# ATmega16U2 device description
Architecture: AVR8; Family: megaAVR
Registers are 8-bit, access not given, no defined reset value unless marked. A register's access mark holds for its fields unless they carry their own. Offsets are from the block's base; [hi:lo] are bit positions.

## TC1 (TC16 module) — Timer/Counter, 16-bit
Instances: TC1 0x00
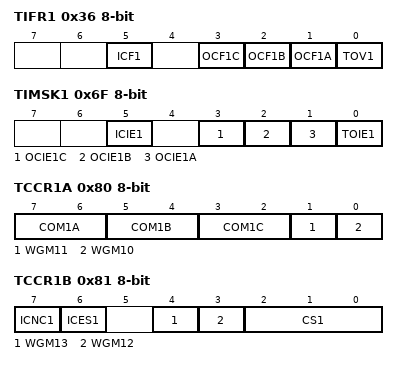
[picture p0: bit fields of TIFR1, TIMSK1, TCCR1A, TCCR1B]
0x36 TIFR1 — Timer/Counter1 Interrupt Flag register
  [5] ICF1 — Input Capture Flag 1
  [3] OCF1C — Output Compare Flag 1C
  [2] OCF1B — Output Compare Flag 1B
  [1] OCF1A — Output Compare Flag 1A
  [0] TOV1 — Timer/Counter1 Overflow Flag
0x6F TIMSK1 — Timer/Counter1 Interrupt Mask Register
  [5] ICIE1 — Timer/Counter1 Input Capture Interrupt Enable
  [3] OCIE1C — Timer/Counter1 Output Compare C Match Interrupt Enable
  [2] OCIE1B — Timer/Counter1 Output Compare B Match Interrupt Enable
  [1] OCIE1A — Timer/Counter1 Output Compare A Match Interrupt Enable
  [0] TOIE1 — Timer/Counter1 Overflow Interrupt Enable
0x80 TCCR1A — Timer/Counter1 Control Register A
  [7:6] COM1A — Compare Output Mode 1A, bits
  [5:4] COM1B — Compare Output Mode 1B, bits
  [3:2] COM1C — Compare Output Mode 1C, bits
  [1] WGM11 — Waveform Generation Mode
  [0] WGM10 — Waveform Generation Mode
0x81 TCCR1B — Timer/Counter1 Control Register B
  [7] ICNC1 — Input Capture 1 Noise Canceler
  [6] ICES1 — Input Capture 1 Edge Select
  [4] WGM13 (bit 2 of the value upward) — Waveform Generation Mode
  [3] WGM12 (bit 2 of the value upward) — Waveform Generation Mode
  [2:0] CS1 — Prescaler source of Timer/Counter 1
    0=No Clock Source (Stopped); 1=Running, No Prescaling; 2=Running, CLK/8; 3=Running, CLK/64; 4=Running, CLK/256; 5=Running, CLK/1024; 6=Running, ExtClk Tx Falling Edge; 7=Running, ExtClk Tx Rising Edge
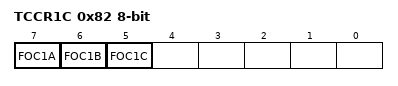
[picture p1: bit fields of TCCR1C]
0x82 TCCR1C — Timer/Counter 1 Control Register C
  [7] FOC1A — Force Output Compare 1A
  [6] FOC1B — Force Output Compare 1B
  [5] FOC1C — Force Output Compare 1C
0x84 TCNT1 16-bit — Timer/Counter1 Bytes
  [15:0] TCNT1 — Timer/Counter1 bits
0x86 ICR1 16-bit — Timer/Counter1 Input Capture Register Bytes
  [15:0] ICR1 — Timer/Counter1 Input Capture bits
0x88 OCR1A 16-bit — Timer/Counter1 Output Compare Register A Bytes
  [15:0] OCR1A — Timer/Counter1 Output Compare A bits
0x8A OCR1B 16-bit — Timer/Counter1 Output Compare Register B Bytes
  [15:0] OCR1B — Timer/Counter1 Output Compare B bits
0x8C OCR1C 16-bit — Timer/Counter1 Output Compare Register C Bytes
  [15:0] OCR1C — Timer/Counter1 Output Compare C bits

## PLL — Phase Locked Loop
Instances: PLL 0x00
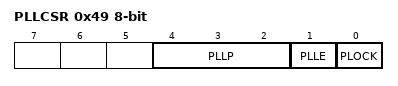
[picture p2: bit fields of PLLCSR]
0x49 PLLCSR — PLL Status and Control register
  [4:2] PLLP — PLL prescaler Bits
    3=Clock/4; 5=Clock/8
  [1] PLLE — PLL Enable Bit
  [0] PLOCK — PLL Lock Status Bit

## USB_DEVICE — USB Device Registers
Instances: USB_DEVICE 0x00
0x63 REGCR — Regulator Control Register
  [0] REGDIS — Regulator Disable
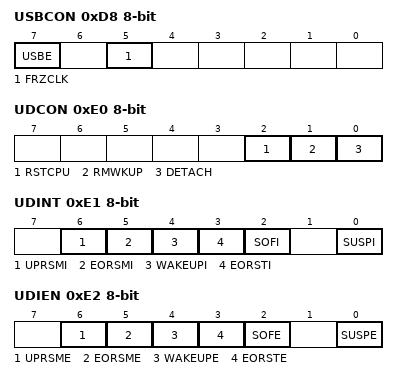
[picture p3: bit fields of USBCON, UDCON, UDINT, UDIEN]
0xD8 USBCON — USB General Control Register
  [7] USBE — USB macro Enable Bit
  [5] FRZCLK — Freeze USB Clock Bit
0xE0 UDCON — USB Device Control Registers
  [2] RSTCPU — USB Reset CPU Bit
  [1] RMWKUP — Remote Wake-up Bit
  [0] DETACH — Detach Bit
0xE1 UDINT — USB Device Interrupt Register
  [6] UPRSMI — Upstream Resume Interrupt Flag
  [5] EORSMI — End Of Resume Interrupt Flag
  [4] WAKEUPI — Wake-up CPU Interrupt Flag
  [3] EORSTI — End Of Reset Interrupt Flag
  [2] SOFI — Start Of Frame Interrupt Flag
  [0] SUSPI — Suspend Interrupt Flag
0xE2 UDIEN — USB Device Interrupt Enable Register
  [6] UPRSME — Upstream Resume Interrupt Enable Bit
  [5] EORSME — End Of Resume Interrupt Enable Bit
  [4] WAKEUPE — Wake-up CPU Interrupt Enable Bit
  [3] EORSTE — End Of Reset Interrupt Enable Bit
  [2] SOFE — Start Of Frame Interrupt Enable Bit
  [0] SUSPE — Suspend Interrupt Enable Bit
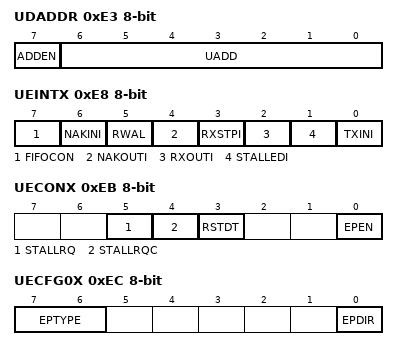
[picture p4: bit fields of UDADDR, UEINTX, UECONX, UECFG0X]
0xE3 UDADDR — USB Device Address Register
  [7] ADDEN — Address Enable Bit
  [6:0] UADD — USB Address Bits
0xE4 UDFNUM 16-bit — USB Device Frame Number High Register
  [10:0] FNUM — Frame Number Upper Flag
0xE6 UDMFN — USB Device Micro Frame Number
  [4] FNCERR — Frame Number CRC Error Flag
0xE8 UEINTX — USB Endpoint Interrupt Register
  [7] FIFOCON — FIFO Control Bit
  [6] NAKINI — NAK IN Received Interrupt Flag
  [5] RWAL — Read/Write Allowed Flag
  [4] NAKOUTI — NAK OUT Received Interrupt Flag
  [3] RXSTPI — Received SETUP Interrupt Flag
  [2] RXOUTI — Received OUT Data Interrupt Flag
  [1] STALLEDI — STALLEDI Interrupt Flag
  [0] TXINI — Transmitter Ready Interrupt Flag
0xE9 UENUM — USB Endpoint Number
  [2:0] EPNUM — Endpoint Number bits
0xEA UERST — USB Endpoint Reset Register
  [4:0] EPRST — Endpoint FIFO Reset Bits
0xEB UECONX — USB Endpoint Control Register
  [5] STALLRQ — STALL Request Handshake Bit
  [4] STALLRQC — STALL Request Clear Handshake Bit
  [3] RSTDT — Reset Data Toggle Bit
  [0] EPEN — Endpoint Enable Bit
0xEC UECFG0X — USB Endpoint Configuration 0 Register
  [7:6] EPTYPE — Endpoint Type Bits
  [0] EPDIR — Endpoint Direction Bit
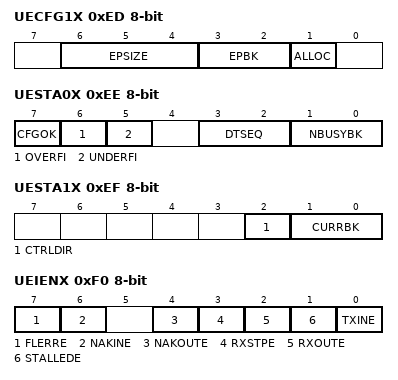
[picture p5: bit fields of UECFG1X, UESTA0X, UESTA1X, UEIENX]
0xED UECFG1X — USB Endpoint Configuration 1 Register
  [6:4] EPSIZE — Endpoint Size Bits
  [3:2] EPBK — Endpoint Bank Bits
  [1] ALLOC — Endpoint Allocation Bit
0xEE UESTA0X — USB Endpoint Status 0 Register
  [7] CFGOK — Configuration Status Flag
  [6] OVERFI — Overflow Error Interrupt Flag
  [5] UNDERFI — Underflow Error Interrupt Flag
  [3:2] DTSEQ — Data Toggle Sequencing Flag
  [1:0] NBUSYBK — Busy Bank Flag
0xEF UESTA1X — USB Endpoint Status 1 Register
  [2] CTRLDIR — Control Direction
  [1:0] CURRBK — Current Bank
0xF0 UEIENX — USB Endpoint Interrupt Enable Register
  [7] FLERRE — Flow Error Interrupt Enable Flag
  [6] NAKINE — NAK IN Interrupt Enable Bit
  [4] NAKOUTE — NAK OUT Interrupt Enable Bit
  [3] RXSTPE — Received SETUP Interrupt Enable Flag
  [2] RXOUTE — Received OUT Data Interrupt Enable Flag
  [1] STALLEDE — Stalled Interrupt Enable Flag
  [0] TXINE — Transmitter Ready Interrupt Enable Flag
0xF1 UEDATX — USB Data Endpoint
  [7:0] DAT — Data bits
0xF2 UEBCLX — USB Endpoint Byte Count Register
  [7:0] BYCT — Byte Count bits
0xF4 UEINT — USB Endpoint Number Interrupt Register
  [4:0] EPINT — Byte Count bits
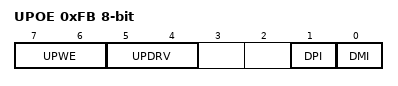
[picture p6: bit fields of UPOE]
0xFB UPOE — USB Software Output Enable register
  [7:6] UPWE — USB Buffers Direct Drive enable configuration
  [5:4] UPDRV — USB direct drive values
  [1] DPI — D+ Input value
  [0] DMI — D- Input value
